# STM32MP25_CM33 register map
File version: 1.3
CPU: CM33 r0p1, little endian, MPU, FPU, vendor SysTick, 8 interrupt priority bits
Registers are 32-bit, read-write, reset 0x0 unless marked. A register's access mark holds for its fields unless they carry their own. Offsets are from the block's base; [hi:lo] are bit positions.

## OCTOSPIM — OCTOSPIM register block
Base 0x40500000
Same registers: OCTOSPIM_S 0x50500000
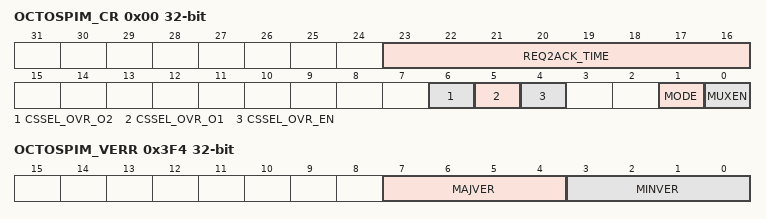
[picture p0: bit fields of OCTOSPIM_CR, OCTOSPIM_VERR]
0x00 OCTOSPIM_CR — OCTOSPIM control register
  [23:16] REQ2ACK_TIME — REQ to ACK time In multiplexed mode (MUXEN = 1), this field defines the time between two transactions. The value is the number of OCTOSPI clock cycles - 1
  [6] CSSEL_OVR_O2 — Chip select selector override setting for OCTOSPI2
    0=the chip select signal from OCTOSPI2 is sent to NCS1; 1=the chip select signal from OCTOSPI2 is sent to NCS2
  [5] CSSEL_OVR_O1 — Chip select selector override setting for OCTOSPI1
    0=the chip select signal from OCTOSPI1 is sent to NCS1; 1=the chip select signal from OCTOSPI1 is sent to NCS2
  [4] CSSEL_OVR_EN — Chip select selector override enable
    0=override not enabled; 1=CSSEL_OVR_O1 and CSSEL_OVR_O2 bit values overwrite the CSSEL signal values coming from OCTOSPI1 and OCTOSPI2
  [1] MODE — OCTOSPIM multiplexing mode
    0=if MUXEN = 0 direct mode, if MUXEN = 1 arbitration mode to output Port 1; 1=if MUXEN = 0 swapped mode, if MUXEN = 1 arbitration mode to output Port 2
  [0] MUXEN — Multiplexed mode enable This bit enables the multiplexing of the two OCTOSPIs.
    0=No multiplexing, hence no arbitration; 1=OCTOSPI1 and OCTOSPI2 are multiplexed over the same bus
0x3F0 OCTOSPIM_HWCFGR ro reset 0x2 — OCTOSPIM hardware configuration register
  [3:0] NUM_PORT — Number of ports This field returns the number of ports in the OCTOSPI I/O manager implementation
0x3F4 OCTOSPIM_VERR ro (reset mask 0xFFFFFF00) — OCTOSPIM version register
  [7:4] MAJVER — OCTOSPIM major version
  [3:0] MINVER — OCTOSPIM minor version
0x3F8 OCTOSPIM_IDR ro reset 0x141041 — OCTOSPIM identification
  [31:0] ID
0x3FC OCTOSPIM_SIDR ro reset 0xA3C5DD01 — OCTOSPIM size identification register
  [31:0] SID — Size identifier This field returns the size of the memory region allocated to registers. The address decoding range is 1 Kbyte.

## VREFBUF — VREFBUF address block description
Base 0x44060000
Same registers: VREFBUF_S 0x54060000
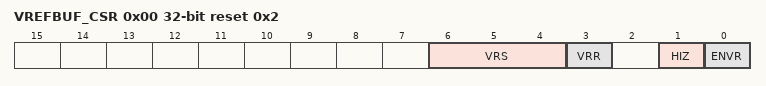
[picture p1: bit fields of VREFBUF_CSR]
0x00 VREFBUF_CSR reset 0x2 — VREFBUF control and status register
  [6:4] VRS — Voltage reference scale These bits select the value generated by the voltage reference buffer. VRS = 000: VREFBUF0 voltage selected. VRS = 001: VREFBUF1 voltage selected. Others: Reserved Refer to the product datasheet for each VREFBUFx voltage setting value. Note: The software can program this bit field only when the VREFBUF is disabled (ENVR=0).
  [3] VRR ro — Voltage reference buffer ready
    0=the voltage reference buffer output is not ready; 1=the voltage reference buffer output reached the requested level
  [1] HIZ — High impedance mode This bit controls the analog switch to connect or not the VsubREF+/sub pin. Refer to Table391: VREF buffer modes for the mode descriptions depending on ENVR bit configuration.
    0=VsubREF+/sub pin is internally connected to the voltage reference buffer output; 1=VsubREF+/sub pin is high impedance
  [0] ENVR — Voltage reference buffer mode enable This bit is used to enable the voltage reference buffer mode.
    0=Internal voltage reference mode disable (external voltage reference mode); 1=Internal voltage reference mode (reference buffer enable or hold mode) enable
0x04 VREFBUF_CCR (reset mask 0xFFFFFF00) — VREFBUF calibration control register
  [5:0] TRIM — Trimming code The TRIM code is a 6-bit unsigned data (minimum 000000, maximum 111111) that is set and updated according the mechanism described below. Reset: TRIM[5:0] is automatically initialized with the VRS=0 trimming value stored in the OTP memory during the production test. VRS change: TRIM[5:0] is automatically initialized with the trimming value (corresponding to VRS setting) stored in the OTP memory during the production test. Write in TRIM[5:0]: User can modify the TRIM[5:0] with an arbitrary value. This is permanently disabling the control of the trimming value with VRS (until the device is reset). Note: If the user application performs the trimming, the trimming code must start from 000000 to 111111 in ascending order.

## WWDG1 — WWDG address block description
Base 0x44050000
Same registers: WWDG2 0x460A0000, WWDG1_S 0x54050000, WWDG2_S 0x560A0000
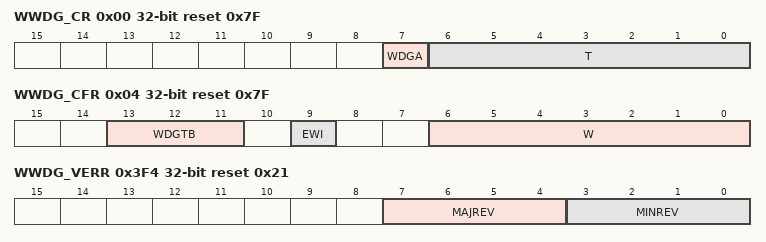
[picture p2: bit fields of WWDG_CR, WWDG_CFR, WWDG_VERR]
0x00 WWDG_CR reset 0x7F — WWDG control register
  [7] WDGA — Activation bit This bit is set by software and only cleared by hardware after a reset. When WDGA=1, the watchdog can generate a reset.
    0=Watchdog disabled; 1=Watchdog enabled
  [6:0] T — 7-bit counter (MSB to LSB) These bits contain the value of the watchdog counter, decremented every (4096 x 2supWDGTB[2:0]/sup) PCLK cycles. A reset is produced when it is decremented from 0x40 to 0x3F (T6 becomes cleared).
0x04 WWDG_CFR reset 0x7F — WWDG configuration register
  [13:11] WDGTB — Timer base The timebase of the prescaler can be modified as follows:
    0=CK counter clock (PCLK div 4096) div 1; 1=CK counter clock (PCLK div 4096) div 2; 2=CK counter clock (PCLK div 4096) div 4; 3=CK counter clock (PCLK div 4096) div 8; 4=CK counter clock (PCLK div 4096) div 16; 5=CK counter clock (PCLK div 4096) div 32; 6=CK counter clock (PCLK div 4096) div 64; 7=CK counter clock (PCLK div 4096) div 128
  [9] EWI — Early wake-up interrupt enable Set by software and cleared by hardware after a reset. When set, an interrupt occurs whenever the counter reaches the value 0x40.
  [6:0] W — 7-bit window value These bits contain the window value to be compared with the down-counter.
0x08 WWDG_SR — WWDG status register
  [0] EWIF — Early wake-up interrupt flag This bit is set by hardware when the counter has reached the value 0x40. It must be cleared by software by writing 0. Writing 1 has no effect. This bit is also set if the interrupt is not enabled.
0x3F0 WWDG_HWCFGR ro reset 0x1000 — WWDG hardware configuration register
  [15:0] PREDIV — The watchdog clock is prescaled by 4096 (PREDIV[15:0]).
0x3F4 WWDG_VERR ro reset 0x21 — WWDG version register
  [7:4] MAJREV — WWDG major revision
  [3:0] MINREV — WWDG minor revision
0x3F8 WWDG_IPIDR ro reset 0x120051 — WWDG identification register
  [31:0] ID — WWDG peripheral identifier
0x3FC WWDG_SIDR ro reset 0xA3C5DD01 — WWDG size identification register
  [31:0] SID — The address decoding range is 1 Kbyte
